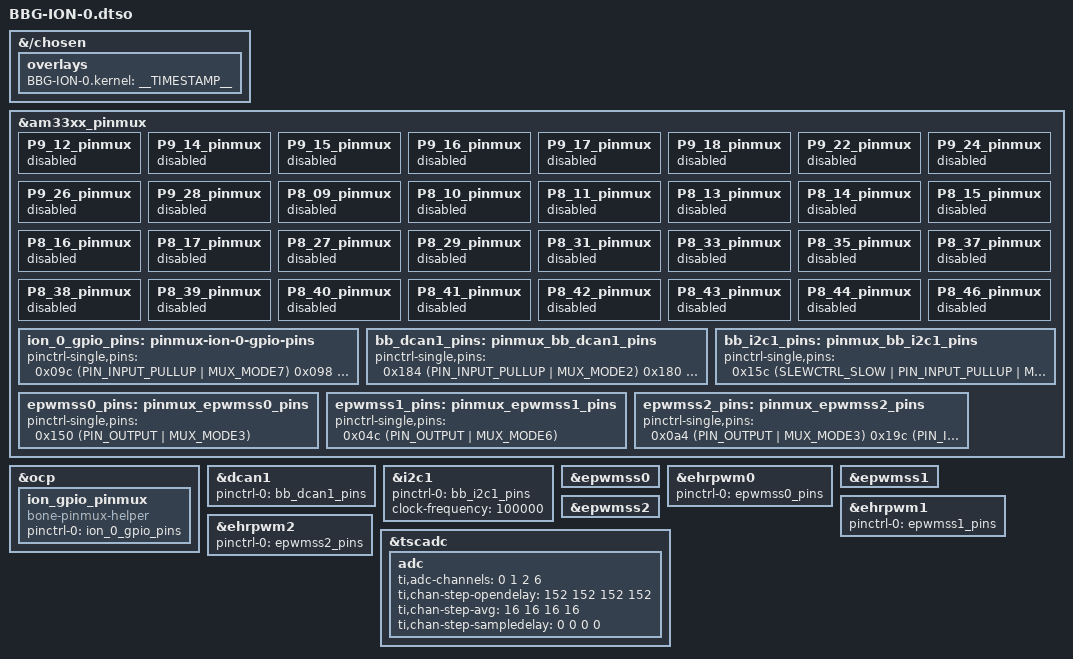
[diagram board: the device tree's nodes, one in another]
/dts-v1/;
/plugin/;

#include <dt-bindings/gpio/gpio.h>
#include <dt-bindings/pinctrl/am33xx.h>

&{/chosen} {
    overlays {
        BBG-ION-0.kernel = __TIMESTAMP__;
    };
};

&am33xx_pinmux {
    /* Move the disabled pinmuxes here, NOT under &ocp */
    P9_12_pinmux { status = "disabled"; };
    P9_14_pinmux { status = "disabled"; };
    P9_15_pinmux { status = "disabled"; };
    P9_16_pinmux { status = "disabled"; };
    P9_17_pinmux { status = "disabled"; };
    P9_18_pinmux { status = "disabled"; };
    P9_22_pinmux { status = "disabled"; };
    P9_24_pinmux { status = "disabled"; };
    P9_26_pinmux { status = "disabled"; };
    P9_28_pinmux { status = "disabled"; };

    P8_09_pinmux { status = "disabled"; };
    P8_10_pinmux { status = "disabled"; };
    P8_11_pinmux { status = "disabled"; };
    P8_13_pinmux { status = "disabled"; };
    P8_14_pinmux { status = "disabled"; };
    P8_15_pinmux { status = "disabled"; };
    P8_16_pinmux { status = "disabled"; };
    P8_17_pinmux { status = "disabled"; };
    P8_27_pinmux { status = "disabled"; };
    P8_29_pinmux { status = "disabled"; };
    P8_31_pinmux { status = "disabled"; };
    P8_33_pinmux { status = "disabled"; };
    P8_35_pinmux { status = "disabled"; };
    P8_37_pinmux { status = "disabled"; };
    P8_38_pinmux { status = "disabled"; };
    P8_39_pinmux { status = "disabled"; };
    P8_40_pinmux { status = "disabled"; };
    P8_41_pinmux { status = "disabled"; };
    P8_42_pinmux { status = "disabled"; };
    P8_43_pinmux { status = "disabled"; };
    P8_44_pinmux { status = "disabled"; };
    P8_46_pinmux { status = "disabled"; };

    ion_0_gpio_pins: pinmux-ion-0-gpio-pins {
        pinctrl-single,pins = <
            0x09c (PIN_INPUT_PULLUP | MUX_MODE7) /*P8_9*/
            0x098 (PIN_OUTPUT_PULLUP | MUX_MODE7) /*P8_10*/
            0x034 (PIN_OUTPUT_PULLUP | MUX_MODE7) /*P8_11*/
            0x024 (PIN_OUTPUT_PULLUP | MUX_MODE7) /*P8_13*/
            0x028 (PIN_OUTPUT_PULLDOWN | MUX_MODE7) /*P8_14*/
            0x03c (PIN_OUTPUT_PULLUP | MUX_MODE7) /*P8_15*/
            0x038 (PIN_OUTPUT_PULLDOWN | MUX_MODE7) /*P8_16*/
            0x02c (PIN_OUTPUT_PULLDOWN | MUX_MODE7) /*P8_17*/
            0x0e0 (PIN_OUTPUT_PULLDOWN | MUX_MODE7) /*P8_27*/
            0x0e4 (PIN_OUTPUT_PULLDOWN | MUX_MODE7) /*P8_29*/
            0x0d8 (PIN_OUTPUT_PULLDOWN | MUX_MODE7) /*P8_31*/
            0x0d4 (PIN_OUTPUT_PULLDOWN | MUX_MODE7) /*P8_33*/
            0x0d0 (PIN_INPUT | MUX_MODE7) /*P8_35*/
            0x0c0 (PIN_OUTPUT_PULLDOWN | MUX_MODE7) /*P8_37*/
            0x0c4 (PIN_OUTPUT_PULLDOWN | MUX_MODE7) /*P8_38*/
            0x0b8 (PIN_OUTPUT_PULLUP | MUX_MODE7) /*P8_39*/
            0x0bc (PIN_OUTPUT_PULLDOWN | MUX_MODE7) /*P8_40*/
            0x0b0 (PIN_OUTPUT_PULLDOWN | MUX_MODE7) /*P8_41*/
            0x0b4 (PIN_OUTPUT_PULLUP | MUX_MODE7) /*P8_42*/
            0x0a8 (PIN_OUTPUT_PULLDOWN | MUX_MODE7) /*P8_43*/
            0x0ac (PIN_OUTPUT_PULLUP | MUX_MODE7) /*P8_44*/
            0x078 (PIN_OUTPUT_PULLUP | MUX_MODE7) /*P9_12*/
            0x048 (PIN_OUTPUT_PULLDOWN | MUX_MODE7) /*P9_14*/
            0x040 (PIN_OUTPUT_PULLDOWN | MUX_MODE7) /*P9_15*/
        >;
    };

    bb_dcan1_pins: pinmux_bb_dcan1_pins {
        pinctrl-single,pins = <
            0x184 (PIN_INPUT_PULLUP | MUX_MODE2) /*P9_24*/
            0x180 (PIN_OUTPUT_PULLUP | MUX_MODE2) /*P9_26*/
        >;
    };

    bb_i2c1_pins: pinmux_bb_i2c1_pins {
        pinctrl-single,pins = <
            0x15c (SLEWCTRL_SLOW | PIN_INPUT_PULLUP | MUX_MODE2) /*P9_17*/
            0x158 (SLEWCTRL_SLOW | PIN_INPUT_PULLUP | MUX_MODE2) /*P9_18*/
        >;
    };

    epwmss0_pins: pinmux_epwmss0_pins {
        pinctrl-single,pins = <
            0x150 (PIN_OUTPUT | MUX_MODE3) /*P9_22*/
        >;
    };

    epwmss1_pins: pinmux_epwmss1_pins {
        pinctrl-single,pins = <
            0x04c (PIN_OUTPUT | MUX_MODE6) /*P9_16*/
        >;
    };

    epwmss2_pins: pinmux_epwmss2_pins {
        pinctrl-single,pins = <
            0x0a4 (PIN_OUTPUT | MUX_MODE3) /*P8_46*/
            0x19c (PIN_INPUT | MUX_MODE4) /*P9_28*/
        >;
    };
};

/* The bone-pinmux-helper must be under &ocp */
&ocp {
    ion_gpio_pinmux {
        compatible = "bone-pinmux-helper";
        status = "okay";
        pinctrl-names = "default";
        pinctrl-0 = <&ion_0_gpio_pins>;
    };
};

&dcan1 {
    status = "okay";
    pinctrl-names = "default";
    pinctrl-0 = <&bb_dcan1_pins>;
};

&i2c1 {
    status = "okay";
    pinctrl-names = "default";
    pinctrl-0 = <&bb_i2c1_pins>;
    clock-frequency = <100000>;
};

&epwmss0 { status = "okay"; };
&ehrpwm0 {
    status = "okay";
    pinctrl-names = "default";
    pinctrl-0 = <&epwmss0_pins>;
};

&epwmss1 { status = "okay"; };
&ehrpwm1 {
    status = "okay";
    pinctrl-names = "default";
    pinctrl-0 = <&epwmss1_pins>;
};

&epwmss2 { status = "okay"; };
&ehrpwm2 {
    status = "okay";
    pinctrl-names = "default";
    pinctrl-0 = <&epwmss2_pins>;
};

&tscadc {
    status = "okay";
    adc {
        ti,adc-channels = <0 1 2 6>;
        ti,chan-step-opendelay = <152 152 152 152>;
        ti,chan-step-avg = <16 16 16 16>;
        ti,chan-step-sampledelay = <0 0 0 0>;
    };
};
